VERSION ""

NS_ :

BS_:

BU_:

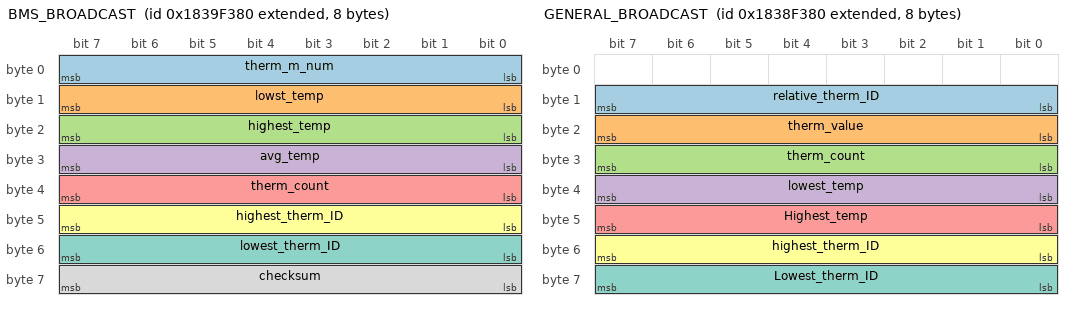
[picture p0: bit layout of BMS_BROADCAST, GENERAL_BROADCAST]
BO_ 2553934720 BMS_BROADCAST: 8 Vector__XXX
	SG_ therm_m_num : 0|8@1+ (1,0) [0|255] "" Vector__XXX
	SG_ lowst_temp : 8|8@1- (1,0) [-128|127] "'C" Vector__XXX
	SG_ highest_temp : 16|8@1- (1,0) [-128|127] "'C" Vector__XXX
	SG_ avg_temp : 24|8@1- (1,0) [-128|127] "'C" Vector__XXX
	SG_ therm_count : 32|8@1+ (1,0) [0|255] "" Vector__XXX
	SG_ highest_therm_ID : 40|8@1+ (1,0) [0|255] "" Vector__XXX
	SG_ lowest_therm_ID : 48|8@1+ (1,0) [0|255] "" Vector__XXX
	SG_ checksum : 56|8@1+ (1,0) [0|255] "" Vector__XXX

BO_ 2553869184 GENERAL_BROADCAST: 8 Vector__XXX
	SG_ relative_therm_ID : 15|8@0+ (1,0) [0|65535] "" Vector__XXX
	SG_ therm_value : 16|8@1- (1,0) [-128|127] "'C" Vector__XXX
	SG_ therm_count : 24|8@1+ (1,0) [0|255] "" Vector__XXX
	SG_ lowest_temp : 32|8@1- (1,0) [-128|127] "'C" Vector__XXX
	SG_ Highest_temp : 40|8@1- (1,0) [-128|127] "'C" Vector__XXX
	SG_ highest_therm_ID : 48|8@1+ (1,0) [0|255] "" Vector__XXX
	SG_ Lowest_therm_ID : 56|8@1+ (1,0) [0|255] "" Vector__XXX

BA_DEF_ SG_  "SPN" INT 0 524287;
BA_DEF_ BO_  "VFrameFormat" ENUM  "StandardCAN","ExtendedCAN","reserved","J1939PG";
BA_DEF_  "DatabaseVersion" STRING ;
BA_DEF_  "BusType" STRING ;
BA_DEF_  "ProtocolType" STRING ;
BA_DEF_  "DatabaseCompiler" STRING ;
BA_DEF_DEF_  "SPN" 0;
BA_DEF_DEF_  "VFrameFormat" "J1939PG";
BA_DEF_DEF_  "DatabaseVersion" "DEMO PLUS";
BA_DEF_DEF_  "BusType" "";
BA_DEF_DEF_  "ProtocolType" "";
BA_DEF_DEF_  "DatabaseCompiler" "";
BA_ "ProtocolType" "J1939";
BA_ "BusType" "CAN";
BA_ "DatabaseCompiler" "CSS ELECTRONICS (WWW.CSSELECTRONICS.COM)";
BA_ "DatabaseVersion" "1.0.0";
BA_ "SPN" SG_ 2364540158 EngineSpeed 190;
BA_ "SPN" SG_ 2566844926 WheelBasedVehicleSpeed 84;
